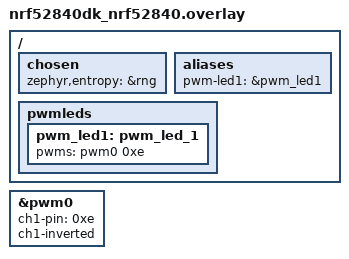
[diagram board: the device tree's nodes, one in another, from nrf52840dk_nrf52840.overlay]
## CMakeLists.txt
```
#
# Copyright (c) 2021 Nordic Semiconductor ASA
#
# SPDX-License-Identifier: LicenseRef-BSD-5-Clause-Nordic
#

cmake_minimum_required(VERSION 3.13.1)

get_filename_component(CHIP_ROOT ../../../../modules/lib/connectedhomeip REALPATH)
get_filename_component(COMMON_ROOT ../common REALPATH)

list(APPEND ZEPHYR_EXTRA_MODULES ${CHIP_ROOT}/config/nrfconnect/chip-module)
find_package(Zephyr HINTS $ENV{ZEPHYR_BASE})

project(chip-light-bulb)

# Temporary get rid of compilation warnings till zephyrproject-rtos/zephyr/pull/31471 is fetched
zephyr_compile_options(-Wno-parentheses)

target_include_directories(app PRIVATE src ${COMMON_ROOT}/src)

target_sources(app PRIVATE
               src/app_task.cpp
               src/lighting_manager.cpp
               src/light_bulb_publish_service.cpp
               src/gen/call-command-handler.cpp
               src/gen/callback-stub.cpp
               src/main.cpp
               src/zcl_callbacks.cpp
               ${COMMON_ROOT}/src/led_widget.cpp
               ${COMMON_ROOT}/src/nfc_widget.cpp
               ${COMMON_ROOT}/src/thread_util.cpp
               ${CHIP_ROOT}/src/app/server/DataModelHandler.cpp
               ${CHIP_ROOT}/src/app/reporting/reporting-default-configuration.cpp
               ${CHIP_ROOT}/src/app/reporting/reporting.cpp
               ${CHIP_ROOT}/src/app/util/af-event.cpp
               ${CHIP_ROOT}/src/app/util/af-main-common.cpp
               ${CHIP_ROOT}/src/app/util/attribute-size.cpp
               ${CHIP_ROOT}/src/app/util/attribute-storage.cpp
               ${CHIP_ROOT}/src/app/util/attribute-table.cpp
               ${CHIP_ROOT}/src/app/util/binding-table.cpp
               ${CHIP_ROOT}/src/app/util/chip-message-send.cpp
               ${CHIP_ROOT}/src/app/util/client-api.cpp
               ${CHIP_ROOT}/src/app/util/ember-print.cpp
               ${CHIP_ROOT}/src/app/util/message.cpp
               ${CHIP_ROOT}/src/app/util/process-cluster-message.cpp
               ${CHIP_ROOT}/src/app/util/process-global-message.cpp
               ${CHIP_ROOT}/src/app/util/util.cpp
               ${CHIP_ROOT}/src/app/clusters/on-off-server/on-off.cpp
               ${CHIP_ROOT}/src/app/clusters/level-control/level-control.cpp)
```

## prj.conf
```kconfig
#
# Copyright (c) 2021 Nordic Semiconductor ASA
#
# SPDX-License-Identifier: LicenseRef-Nordic-5-Clause
#

# Enable CHIP
CONFIG_CHIP=y
CONFIG_CHIP_PROJECT_CONFIG="src/chip_project_config.h"
CONFIG_STD_CPP14=y

# General networking settings
CONFIG_NETWORKING=y
CONFIG_NET_IPV6_NBR_CACHE=n
CONFIG_NET_IPV6_MLD=n
CONFIG_NET_SOCKETS_POLL_MAX=5

# Enable OpenThread MTD
CONFIG_NET_L2_OPENTHREAD=y

CONFIG_OPENTHREAD_MTD=y
CONFIG_OPENTHREAD_FTD=n
CONFIG_OPENTHREAD_SLAAC=y
CONFIG_OPENTHREAD_MTD_NETDIAG=y
CONFIG_OPENTHREAD_MANUAL_START=y
CONFIG_OPENTHREAD_THREAD_STACK_SIZE=6144
CONFIG_OPENTHREAD_NUM_MESSAGE_BUFFERS=64

CONFIG_OPENTHREAD_PANID=4660
CONFIG_OPENTHREAD_CHANNEL=15
CONFIG_OPENTHREAD_NETWORK_NAME="OpenThread"
CONFIG_OPENTHREAD_XPANID="11:11:11:11:22:22:22:22"

# Enable Bluetooth Low Energy
CONFIG_BT=y
CONFIG_BT_PERIPHERAL=y
CONFIG_BT_DEVICE_APPEARANCE=0
CONFIG_BT_DEVICE_NAME_DYNAMIC=y
CONFIG_BT_DEVICE_NAME_MAX=15
CONFIG_BT_DEVICE_NAME="ChipLight"
CONFIG_BT_MAX_CONN=1
CONFIG_BT_PHY_UPDATE=n
CONFIG_BT_CTLR_PHY_2M=n
CONFIG_BT_SMP=y
CONFIG_BT_PRIVACY=y
CONFIG_BT_MAX_PAIRED=0
CONFIG_BT_BONDABLE=n
CONFIG_BT_TINYCRYPT_ECC=n
CONFIG_BT_SMP_OOB_LEGACY_PAIR_ONLY=y
CONFIG_SDC_MAX_CONN_EVENT_LEN_DEFAULT=3000

# Use NFC to share commissioning information
CONFIG_CHIP_NFC_COMMISSIONING=y

# Use nrf_security
CONFIG_OPENTHREAD_NRF_SECURITY_CHOICE=y

CONFIG_CC3XX_BACKEND=y
CONFIG_OBERON_BACKEND=y

CONFIG_MBEDTLS_ENABLE_HEAP=y
CONFIG_MBEDTLS_HEAP_SIZE=15360
CONFIG_MBEDTLS_TLS_LIBRARY=y
CONFIG_NRF_SECURITY_ADVANCED=y

CONFIG_MBEDTLS_AES_C=y
CONFIG_MBEDTLS_ECP_C=y
CONFIG_MBEDTLS_ECP_DP_SECP256R1_ENABLED=y
CONFIG_MBEDTLS_CTR_DRBG_C=y
CONFIG_MBEDTLS_CIPHER_MODE_CTR=y
CONFIG_MBEDTLS_ECJPAKE_C=y
CONFIG_MBEDTLS_SHA256_C=y
CONFIG_MBEDTLS_PK_C=y
CONFIG_MBEDTLS_PK_WRITE_C=y
CONFIG_MBEDTLS_X509_CREATE_C=y
CONFIG_MBEDTLS_X509_CSR_WRITE_C=y

# Use SHA256 implementation from Oberon
CONFIG_CHOICE_OBERON_MBEDTLS_SHA256_C=y

# Disable unneeded crypto operations
CONFIG_MBEDTLS_SHA512_C=n
CONFIG_MBEDTLS_CIPHER_MODE_XTS=n
CONFIG_MBEDTLS_CHACHA20_C=n
CONFIG_MBEDTLS_POLY1305_C=n
CONFIG_MBEDTLS_CHACHAPOLY_C=n
CONFIG_MBEDTLS_GCM_C=n
CONFIG_MBEDTLS_RSA_C=n
CONFIG_OBERON_MBEDTLS_AES_C=n

# Add support for LEDs and buttons on Nordic development kits
CONFIG_DK_LIBRARY=y
CONFIG_PWM=y

# Other settings
CONFIG_LOG=y
CONFIG_LOG_MODE_MINIMAL=y
CONFIG_MAIN_STACK_SIZE=8192
CONFIG_INIT_STACKS=y
CONFIG_HW_STACK_PROTECTION=y
CONFIG_THREAD_NAME=y
CONFIG_SHELL=y
```

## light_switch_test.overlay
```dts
CONFIG_CHIP_ENABLE_RENDEZVOUS_BYPASS=y
```

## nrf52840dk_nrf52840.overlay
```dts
/*
 * Copyright (c) 2021 Nordic Semiconductor ASA
 *
 * SPDX-License-Identifier: LicenseRef-BSD-5-Clause-Nordic
 */

/ {

	/*
	* In some default configurations within the nRF Connect SDK,
	* e.g. on nRF52840, the chosen zephyr,entropy node is &cryptocell.
	* This devicetree overlay ensures that default is overridden wherever it
	* is set, as this application uses the RNG node for entropy exclusively.
	*/

	chosen {
		zephyr,entropy = &rng;
	};

	/*
	* By default, PWM module is only configured for led0 (LED1 on the board).
	* The lighting-app, however, uses LED2 to show the state of the lighting,
	* including its brightness level.
	*/
	aliases {
		pwm-led1 = &pwm_led1;
	};

	pwmleds {
		pwm_led1: pwm_led_1 {
			pwms = < &pwm0 0xe >;
		};
	};

};

&pwm0 {
	ch1-pin = < 0xe >;
	ch1-inverted;
};
```

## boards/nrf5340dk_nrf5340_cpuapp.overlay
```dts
/*
 * Copyright (c) 2021 Nordic Semiconductor ASA
 *
 * SPDX-License-Identifier: LicenseRef-Nordic-5-Clause
 */

/ {
	/*
	* By default, PWM module is only configured for led0 (LED1 on the board).
	* The lighting-app, however, uses LED2 to show the state of the lighting,
	* including its brightness level.
	*/
	aliases {
		pwm-led1 = &pwm_led1;
	};

	pwmleds {
		compatible = "pwm-leds";
		pwm_led1: pwm_led_1 {
			pwms = < &pwm0 0x1d >;
		};
	};

};

&pwm0 {
	ch1-pin = < 0x1d >;
	ch1-inverted;
};
```

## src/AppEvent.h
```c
/*
 * Copyright (c) 2020 Nordic Semiconductor ASA
 *
 * SPDX-License-Identifier: LicenseRef-BSD-5-Clause-Nordic
 */

#pragma once

#include <cstdint>

struct AppEvent {
	enum LightEventType : uint8_t {
		On,
		Off,
		Toggle,
		Level
	};

	enum OtherEventType : uint8_t {
		FactoryReset = Level + 1,
		StartThread,
		StartBleAdvertising,
		PublishLightBulbService
	};

	AppEvent() = default;

	AppEvent(LightEventType type, uint8_t value, bool chipInitiated) : Type(type), Value(value), LightEvent{chipInitiated}
	{
	}

	AppEvent(OtherEventType type) : Type(type)
	{
	}

	uint8_t Type;
	uint8_t Value;

	union {
		struct {
			// was the event triggered by CHIP Data Model layer
			bool ChipInitiated;
		} LightEvent;
	};
};
```

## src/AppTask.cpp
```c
/*
 * Copyright (c) 2020 Nordic Semiconductor ASA
 *
 * SPDX-License-Identifier: LicenseRef-BSD-5-Clause-Nordic
 */

#include "AppTask.h"

#include "LightingManager.h"
#include "QRCodeUtil.h"
#include "Server.h"
#include "LEDWidget.h"
#include "ThreadUtil.h"
#include "LightBulbPublishService.h"

#ifdef CONFIG_CHIP_NFC_COMMISSIONING
#include "NFCWidget.h"
#endif

#include "attribute-storage.h"
#include "gen/cluster-id.h"

#include <platform/CHIPDeviceLayer.h>

#include <dk_buttons_and_leds.h>
#include <logging/log.h>
#include <zephyr.h>

using namespace ::chip::DeviceLayer;

LOG_MODULE_DECLARE(app);
K_MSGQ_DEFINE(sAppEventQueue, sizeof(AppEvent), AppTask::APP_EVENT_QUEUE_SIZE, alignof(AppEvent));

namespace {
LEDWidget sStatusLED;
LEDWidget sLightLED;

#ifdef CONFIG_CHIP_NFC_COMMISSIONING
NFCWidget sNFC;
#endif

LightBulbPublishService sLightBulbPublishService;

bool sIsThreadProvisioned;
bool sIsThreadEnabled;
bool sIsThreadAttached;
bool sIsPairedToAccount;
bool sHaveBLEConnections;
bool sHaveServiceConnectivity;
} // namespace

AppTask AppTask::sAppTask;

int AppTask::Init()
{
	// Initialize LEDs
	LEDWidget::InitGpio();

	sStatusLED.Init(DK_LED1);
	sLightLED.Init(DK_LED2);
	sLightLED.Set(false);

	// Initialize buttons
	int ret = dk_buttons_init(ButtonEventHandler);
	if (ret) {
		LOG_ERR("dk_buttons_init() failed");
		return ret;
	}

	// Initialize light manager
	LightingMgr().Init(DT_PWMS_LABEL(DT_ALIAS(pwm_led1)),
			   DT_PWMS_CHANNEL(DT_ALIAS(pwm_led1)));

	LightingMgr().SetCallbacks(ActionInitiated, ActionCompleted);

	// Init ZCL Data Model and start server
	InitServer();
	PrintQRCode(chip::RendezvousInformationFlags::kBLE);

#ifdef CONFIG_CHIP_NFC_COMMISSIONING
	ret = sNFC.Init(ConnectivityMgr());
	if (ret) {
		LOG_ERR("NFC initialization failed");
		return ret;
	}

	PlatformMgr().AddEventHandler(AppTask::ThreadProvisioningHandler, 0);
#endif

	sLightBulbPublishService.Init();

	return 0;
}

int AppTask::StartApp()
{
	int ret = Init();

	if (ret) {
		LOG_ERR("AppTask.Init() failed");
		return ret;
	}

	AppEvent event = {};

	while (true) {
		ret = k_msgq_get(&sAppEventQueue, &event, K_MSEC(10));

		while (!ret) {
			DispatchEvent(event);
			ret = k_msgq_get(&sAppEventQueue, &event, K_NO_WAIT);
		}

		// Collect connectivity and configuration state from the CHIP stack.  Because the
		// CHIP event loop is being run in a separate task, the stack must be locked
		// while these values are queried.  However we use a non-blocking lock request
		// (TryLockChipStack()) to avoid blocking other UI activities when the CHIP
		// task is busy (e.g. with a long crypto operation).

		if (PlatformMgr().TryLockChipStack()) {
			sIsThreadProvisioned = ConnectivityMgr().IsThreadProvisioned();
			sIsThreadEnabled = ConnectivityMgr().IsThreadEnabled();
			sIsThreadAttached = ConnectivityMgr().IsThreadAttached();
			sHaveBLEConnections = (ConnectivityMgr().NumBLEConnections() != 0);
			sHaveServiceConnectivity = ConnectivityMgr().HaveServiceConnectivity();
			PlatformMgr().UnlockChipStack();
		}

		// Consider the system to be "fully connected" if it has service
		// connectivity and it is able to interact with the service on a regular basis.
		bool isFullyConnected = sHaveServiceConnectivity;

		// Update the status LED.
		//
		// If system has "full connectivity", keep the LED On constantly.
		//
		// If thread and service provisioned, but not attached to the thread network yet OR no
		// connectivity to the service OR subscriptions are not fully established
		// THEN blink the LED Off for a short period of time.
		//
		// If the system has ble connection(s) uptill the stage above, THEN blink the LEDs at an even
		// rate of 100ms.
		//
		// Otherwise, blink the LED ON for a very short time.
		if (isFullyConnected) {
			sStatusLED.Set(true);
		} else if (sIsThreadProvisioned && sIsThreadEnabled && sIsPairedToAccount) {
			sStatusLED.Blink(950, 50);
		} else if (sHaveBLEConnections) {
			sStatusLED.Blink(100, 100);
		} else {
			sStatusLED.Blink(50, 950);
		}

		sStatusLED.Animate();
	}
}

void AppTask::PostEvent(const AppEvent& aEvent)
{
	if (k_msgq_put(&sAppEventQueue, &aEvent, K_NO_WAIT)) {
		LOG_INF("Failed to post event to app task event queue");
	}
}

void AppTask::UpdateClusterState()
{
	uint8_t onOff = LightingMgr().IsTurnedOn();

	// write the new on/off value
	EmberAfStatus status = emberAfWriteAttribute(1, ZCL_ON_OFF_CLUSTER_ID, ZCL_ON_OFF_ATTRIBUTE_ID, CLUSTER_MASK_SERVER, &onOff,
						     ZCL_BOOLEAN_ATTRIBUTE_TYPE);

	if (status != EMBER_ZCL_STATUS_SUCCESS) {
		LOG_ERR("Updating on/off cluster failed: %x", status);
	}

	uint8_t level = LightingMgr().GetLevel();

	status = emberAfWriteAttribute(1, ZCL_LEVEL_CONTROL_CLUSTER_ID, ZCL_CURRENT_LEVEL_ATTRIBUTE_ID, CLUSTER_MASK_SERVER, &level,
					ZCL_DATA8_ATTRIBUTE_TYPE);

	if (status != EMBER_ZCL_STATUS_SUCCESS) {
		LOG_ERR("Updating level cluster failed: %x", status);
	}
}

void AppTask::DispatchEvent(const AppEvent& aEvent)
{
	switch (aEvent.Type) {
	case AppEvent::On:
		LightingMgr().InitiateAction(LightingManager::Action::On, aEvent.Value, aEvent.LightEvent.ChipInitiated);
		break;
	case AppEvent::Off:
		LightingMgr().InitiateAction(LightingManager::Action::Off, aEvent.Value, aEvent.LightEvent.ChipInitiated);
		break;
	case AppEvent::Toggle:
		LightingMgr().InitiateAction(LightingMgr().IsTurnedOn() ? LightingManager::Action::Off : LightingManager::Action::On,
					     aEvent.Value, aEvent.LightEvent.ChipInitiated);
		break;
	case AppEvent::Level:
		LightingMgr().InitiateAction(LightingManager::Action::Level, aEvent.Value, aEvent.LightEvent.ChipInitiated);
		break;
	case AppEvent::FactoryReset:
		LOG_INF("Factory Reset triggered");
		ConfigurationMgr().InitiateFactoryReset();
		break;
	case AppEvent::StartThread:
		StartThreadHandler();
		break;
	case AppEvent::StartBleAdvertising:
		StartBLEAdvertisingHandler();
		break;
	case AppEvent::PublishLightBulbService:
		sLightBulbPublishService.Publish();
		break;
	default:
		LOG_INF("Unknown event received");
		break;
	}
}

void AppTask::ActionInitiated(LightingManager::Action aAction)
{
    if (aAction == LightingManager::Action::On)
    {
        LOG_INF("Turn On Action has been initiated");
    }
    else if (aAction == LightingManager::Action::Off)
    {
        LOG_INF("Turn Off Action has been initiated");
    }
    else if (aAction == LightingManager::Action::Level)
    {
        LOG_INF("Level Action has been initiated");
    }
}

void AppTask::ActionCompleted(LightingManager::Action aAction)
{
    if (aAction == LightingManager::Action::On)
    {
        LOG_INF("Turn On Action has been completed");
    }
    else if (aAction == LightingManager::Action::Off)
    {
        LOG_INF("Turn Off Action has been completed");
    }
    else if (aAction == LightingManager::Action::Level)
    {
        LOG_INF("Level Action has been completed");
    }

    if (!LightingMgr().IsActionChipInitiated())
    {
        sAppTask.UpdateClusterState();
    }
}

void AppTask::StartThreadHandler()
{
	if (!ConnectivityMgr().IsThreadProvisioned()) {
		StartDefaultThreadNetwork();
		LOG_INF("Device is not commissioned to a Thread network. Starting with the default configuration");
	} else {
		LOG_INF("Device is commissioned to a Thread network");
	}

	sLightBulbPublishService.Start(10000, 1000);
}

void AppTask::StartBLEAdvertisingHandler()
{
    if (!sNFC.IsTagEmulationStarted())
    {
        if (!(GetAppTask().StartNFCTag() < 0))
        {
            LOG_INF("Started NFC Tag emulation");
        }
        else
        {
            LOG_ERR("Starting NFC Tag failed");
        }
    }
    else
    {
        LOG_INF("NFC Tag emulation is already started");
    }

	if (!ConnectivityMgr().IsBLEAdvertisingEnabled()) {
		ConnectivityMgr().SetBLEAdvertisingEnabled(true);
		LOG_INF("Enabled BLE Advertising");
	} else {
		LOG_INF("BLE Advertising is already enabled");
	}
}

#ifdef CONFIG_CHIP_NFC_COMMISSIONING
int AppTask::StartNFCTag()
{
	// Get QR Code and emulate its content using NFC tag
	uint32_t setupPinCode;
	std::string QRCode;

	int result = GetQRCode(setupPinCode, QRCode, chip::RendezvousInformationFlags::kBLE);

	VerifyOrExit(!result, ChipLogError(AppServer, "Getting QR code payload failed"));

	result = sNFC.StartTagEmulation(QRCode.c_str(), QRCode.size());
	VerifyOrExit(result >= 0, ChipLogError(AppServer, "Starting NFC Tag emulation failed"));

exit:
	return result;
}

void AppTask::ThreadProvisioningHandler(const ChipDeviceEvent *event, intptr_t arg)
{
	ARG_UNUSED(arg);
	if ((event->Type == DeviceEventType::kServiceProvisioningChange) && ConnectivityMgr().IsThreadProvisioned()) {
		const int result = sNFC.StopTagEmulation();
		if (result) {
			LOG_ERR("Stopping NFC Tag emulation failed");
		}
	}
}
#endif

void AppTask::ButtonEventHandler(uint32_t button_state, uint32_t has_changed)
{
	if (DK_BTN1_MSK & button_state & has_changed) {
		GetAppTask().PostEvent(AppEvent{ AppEvent::FactoryReset });
	}

	if (DK_BTN2_MSK & button_state & has_changed) {
		GetAppTask().PostEvent(AppEvent{ AppEvent::Toggle, 0, false });
	}

	if (DK_BTN3_MSK & button_state & has_changed) {
		GetAppTask().PostEvent(AppEvent{ AppEvent::StartThread });
	}

	if (DK_BTN4_MSK & button_state & has_changed) {
		GetAppTask().PostEvent(AppEvent{ AppEvent::StartBleAdvertising });
	}
}
```

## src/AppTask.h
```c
/*
 * Copyright (c) 2020 Nordic Semiconductor ASA
 *
 * SPDX-License-Identifier: LicenseRef-BSD-5-Clause-Nordic
 */

#pragma once

#include "AppEvent.h"
#include "LightingManager.h"

#include <platform/CHIPDeviceLayer.h>

struct k_timer;

class AppTask {
public:
	static constexpr size_t APP_EVENT_QUEUE_SIZE = 10;

	int StartApp();

	void PostEvent(const AppEvent& aEvent);
	void UpdateClusterState();

private:
	int Init();

	void DispatchEvent(const AppEvent& event);
	void CompleteLockActionHandler();
	void StartThreadHandler();
	void StartBLEAdvertisingHandler();

#ifdef CONFIG_CHIP_NFC_COMMISSIONING
	int StartNFCTag();
#endif

	static void ActionInitiated(LightingManager::Action aAction);
	static void ActionCompleted(LightingManager::Action aAction);
	static void ButtonEventHandler(uint32_t buttons_state, uint32_t has_changed);
	static void ThreadProvisioningHandler(const chip::DeviceLayer::ChipDeviceEvent *event, intptr_t arg);

	friend AppTask & GetAppTask();

	static AppTask sAppTask;
};

inline AppTask & GetAppTask()
{
	return AppTask::sAppTask;
}
```

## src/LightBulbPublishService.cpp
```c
/*
 * Copyright (c) 2020 Nordic Semiconductor ASA
 *
 * SPDX-License-Identifier: LicenseRef-BSD-5-Clause-Nordic
 */
#include "LightBulbPublishService.h"

#include "AppTask.h"

#include <logging/log.h>
#include <zephyr.h>

#include <openthread/message.h>
#include <openthread/udp.h>
#include <platform/OpenThread/OpenThreadUtils.h>

#include <inet/InetConfig.h>
#include <platform/CHIPDeviceLayer.h>
#include <transport/TransportMgr.h>
#include <transport/raw/UDP.h>

LOG_MODULE_DECLARE(app);

// Pointer to the LightBulbPublishService instance needed by static
// PublishTimerHandler method
static LightBulbPublishService* sLightBulbPublishService;

const char PUBLISH_SERVICE_PAYLOAD[] = "chip-light-bulb";
const char PUBLISH_DEST_ADDR[] = "ff03::1:12345";

using namespace ::chip;
using namespace ::chip::Inet;
using namespace ::chip::Transport;
using namespace ::chip::DeviceLayer;

void LightBulbPublishService::Init()
{
    // Set pointer to the current instance
    sLightBulbPublishService = this;
    mIsServiceStarted = false;

    // Initialize timer
    k_timer_init(&mPublishTimer, &PublishTimerHandler, nullptr);
    k_timer_user_data_set(&mPublishTimer, this);

    // Initialize UDP endpoint
    UdpListenParameters udpParams(&chip::DeviceLayer::InetLayer);
    udpParams.SetAddressType(kIPAddressType_IPv6);
    udpParams.SetInterfaceId(INET_NULL_INTERFACEID);
    udpParams.SetListenPort(SERVICE_UDP_PORT);
    if (mUdp.Init(udpParams))
    {
        LOG_ERR("LightBulbPublishService initialization failed");
    }

    mMessageId = 0;
    IPAddress::FromString(PUBLISH_DEST_ADDR, mPublishDestAddr);
}

void LightBulbPublishService::Start(uint32_t aTimeoutInMs, uint32_t aIntervalInMs)
{
    if (!mIsServiceStarted)
    {
        if (aTimeoutInMs >= aIntervalInMs)
        {
            LOG_INF("Started Publish service");

            mPublishInterval = aIntervalInMs;
            // Calculate number of publish iterations to do considering given timeout and interval values.
            mPublishIterations = aTimeoutInMs / aIntervalInMs;
            mIsServiceStarted = true;

            k_timer_start(&mPublishTimer, K_MSEC(aIntervalInMs), K_NO_WAIT);
        }
        else
        {
            LOG_ERR("Publish service cannot be started: service timeout is greater than interval");
        }
    }
    else
    {
        LOG_INF("Publish service is already running");
    }
}

void LightBulbPublishService::Stop()
{
    if (mIsServiceStarted)
    {
        LOG_INF("Stopped Publish service");

        k_timer_stop(&mPublishTimer);

        mIsServiceStarted = false;
        mMessageId = 0;
    }
    else
    {
        LOG_INF("Publish service is not running");
    }
}

void LightBulbPublishService::Publish()
{
    if (!chip::DeviceLayer::ConnectivityMgrImpl().IsThreadAttached())
    {
        return;
    }

    const uint16_t payloadLength = sizeof(PUBLISH_SERVICE_PAYLOAD);

    chip::System::PacketBufferHandle buffer = chip::System::PacketBuffer::NewWithAvailableSize(payloadLength);
    if (!buffer.IsNull())
    {
        memcpy(buffer->Start(), PUBLISH_SERVICE_PAYLOAD, payloadLength);
        buffer->SetDataLength(payloadLength);

        // Subsequent messages are assumed to have increasing IDs.
        PacketHeader header;
        header.SetMessageId(mMessageId++);

        if (mUdp.SendMessage(header, Transport::PeerAddress::UDP(mPublishDestAddr), std::move(buffer)))
        {
            LOG_INF("LightBulbPublishService message send successfully");
        }
        else
        {
            LOG_INF("LightBulbPublishService message sending failed");
        }
    }
}

void LightBulbPublishService::PublishTimerHandler(k_timer *aTimer)
{
    if (sLightBulbPublishService->mPublishIterations > 0)
    {
        GetAppTask().PostEvent(AppEvent{ AppEvent::PublishLightBulbService });
        k_timer_start(&(sLightBulbPublishService->mPublishTimer), K_MSEC(sLightBulbPublishService->mPublishInterval), K_NO_WAIT);
        sLightBulbPublishService->mPublishIterations--;
    }
    else
    {
        sLightBulbPublishService->Stop();
    }
}
```

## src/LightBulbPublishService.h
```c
/*
 * Copyright (c) 2020 Nordic Semiconductor ASA
 *
 * SPDX-License-Identifier: LicenseRef-BSD-5-Clause-Nordic
 */
#pragma once

#include <inet/InetConfig.h>
#include <transport/raw/UDP.h>

#include <zephyr.h>

#include <string>

using namespace ::chip::Inet;
using namespace ::chip::Transport;

class LightBulbPublishService
{
public:
    void Init();
    void Start(uint32_t aTimeoutInMs, uint32_t aIntervalInMs);
    void Stop();
    void Publish();
    
private:
    friend LightBulbPublishService & LightBulbPublishServ();

    static constexpr uint16_t SERVICE_UDP_PORT = 13000;

    bool mIsServiceStarted;
    uint32_t mPublishInterval;
    uint32_t mPublishIterations;
    k_timer mPublishTimer;
    UDP mUdp;
    uint32_t mMessageId;
    IPAddress mPublishDestAddr;

    static void PublishTimerHandler(k_timer *aTimer);

};
```

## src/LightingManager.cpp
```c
/*
 * Copyright (c) 2020 Nordic Semiconductor ASA
 *
 * SPDX-License-Identifier: LicenseRef-BSD-5-Clause-Nordic
 */

#include "LightingManager.h"

#include <logging/log.h>

#include <drivers/pwm.h>
#include <zephyr.h>

LOG_MODULE_DECLARE(app);

LightingManager LightingManager::sLight;

int LightingManager::Init(const char * pwmDeviceName, uint32_t pwmChannel)
{
    // We use a gpioPin instead of a LEDWidget here because we want to use PWM
    // and other features instead of just on/off.

    mState      = State::On;
    mLevel      = kMaxLevel;
    mPwmDevice  = device_get_binding(pwmDeviceName);
    mPwmChannel = pwmChannel;

    if (!mPwmDevice)
    {
        LOG_ERR("Cannot find PWM device %s", log_strdup(pwmDeviceName));
        return -ENODEV;
    }

    Set(false);
    return 0;
}

void LightingManager::SetCallbacks(LightingCallback_fn aActionInitiated_CB, LightingCallback_fn aActionCompleted_CB)
{
    mActionInitiated_CB = aActionInitiated_CB;
    mActionCompleted_CB = aActionCompleted_CB;
}

bool LightingManager::InitiateAction(Action aAction, uint8_t value, bool chipInitiated)
{
    bool actionInitiated = false;
    State newState;

    // Initiate On/Off Action only when the previous one is complete.
    if (mState == State::Off && aAction == Action::On)
    {
        actionInitiated = true;
        newState        = State::On;
    }
    else if (mState == State::On && aAction == Action::Off)
    {
        actionInitiated = true;
        newState        = State::Off;
    }
    else if (aAction == Action::Level && value != mLevel)
    {
        actionInitiated = true;
        newState = (value == 0) ? State::Off : State::On;
    }

    if (actionInitiated)
    {
        if (mActionInitiated_CB)
        {
            mActionInitiated_CB(aAction);
        }

        if (aAction == Action::On || aAction == Action::Off)
        {
            Set(newState == State::On);
        }
        else if (aAction == Action::Level)
        {
            SetLevel(value);
        }

        mChipInitiatedAction = chipInitiated;

        if (mActionCompleted_CB)
        {
            mActionCompleted_CB(aAction);
        }
    }

    return actionInitiated;
}

void LightingManager::SetLevel(uint8_t aLevel)
{
    LOG_INF("Setting brightness level to %u", aLevel);
    mLevel = aLevel;
    UpdateLight();
}

void LightingManager::Set(bool aOn)
{
    mState = aOn ? State::On : State::Off;
    UpdateLight();
}

void LightingManager::UpdateLight()
{
    constexpr uint32_t kPwmWidthUs = 1000u;
    const uint8_t level            = mState == State::On ? mLevel : 0;
    pwm_pin_set_usec(mPwmDevice, mPwmChannel, kPwmWidthUs, kPwmWidthUs * level / kMaxLevel, 0);
}
```

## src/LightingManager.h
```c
/*
 * Copyright (c) 2020 Nordic Semiconductor ASA
 *
 * SPDX-License-Identifier: LicenseRef-BSD-5-Clause-Nordic
 */

#pragma once

#include "AppEvent.h"

#include <cstdint>
#include <drivers/gpio.h>

class LightingManager
{
public:
    enum class Action : uint8_t
    {
        On,
        Off,
        Level
    };

    enum class State : uint8_t
    {
        On,
        Off
    };

    using LightingCallback_fn = void (*)(Action);

    int Init(const char * pwmDeviceName, uint32_t pwmChannel);
    bool IsTurnedOn() const { return mState == State::On; }
    uint8_t GetLevel() const { return mLevel; }
    bool IsActionChipInitiated() const { return mChipInitiatedAction; }
    bool InitiateAction(Action aAction, uint8_t value, bool chipInitiated);
    void SetCallbacks(LightingCallback_fn aActionInitiated_CB, LightingCallback_fn aActionCompleted_CB);

private:
    static constexpr uint8_t kMaxLevel = 255;

    friend LightingManager & LightingMgr();
    State mState;
    uint8_t mLevel;
    const device * mPwmDevice;
    uint32_t mPwmChannel;
    bool mChipInitiatedAction;

    LightingCallback_fn mActionInitiated_CB;
    LightingCallback_fn mActionCompleted_CB;

    void Set(bool aOn);
    void SetLevel(uint8_t aLevel);
    void UpdateLight();

    static LightingManager sLight;
};

inline LightingManager & LightingMgr(void)
{
    return LightingManager::sLight;
}
```

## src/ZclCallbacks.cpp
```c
/*
 * Copyright (c) 2020 Nordic Semiconductor ASA
 *
 * SPDX-License-Identifier: LicenseRef-BSD-5-Clause-Nordic
 */

#include <support/logging/CHIPLogging.h>

#include "AppTask.h"
#include "LightingManager.h"

#include "af.h"
#include "gen/attribute-id.h"
#include "gen/cluster-id.h"
#include <app/util/af-types.h>

using namespace ::chip;

void emberAfPostAttributeChangeCallback(EndpointId endpoint, ClusterId clusterId, AttributeId attributeId, uint8_t mask,
					uint16_t manufacturerCode, uint8_t type, uint8_t size, uint8_t *value)
{
	ChipLogProgress(Zcl, "Cluster callback: %d", clusterId);

	if (clusterId == ZCL_ON_OFF_CLUSTER_ID) 
	{
		if (attributeId != ZCL_ON_OFF_ATTRIBUTE_ID) 
		{
			ChipLogProgress(Zcl, "Unknown attribute ID: %d", attributeId);
			return;
		}

		GetAppTask().PostEvent(AppEvent(*value ? AppEvent::On : AppEvent::Off, *value, true));
	}
	else if (clusterId == ZCL_LEVEL_CONTROL_CLUSTER_ID) 
	{
		if (attributeId != ZCL_MOVE_TO_LEVEL_COMMAND_ID)
		{
			ChipLogProgress(Zcl, "Unknown attribute ID: %d", attributeId);
			return;
		}

		if (size == 1)
		{
			ChipLogProgress(Zcl, "emberAfPostAttributeChangeCallback %d", *value);
			GetAppTask().PostEvent(AppEvent(AppEvent::Level, *value, true));
		}
		else
		{
			ChipLogError(Zcl, "wrong length for level: %d", size);
		}
	}
	else 
	{
		ChipLogProgress(Zcl, "Unknown cluster ID: %d", clusterId);
		return;
	}
}

/** @brief OnOff Cluster Init
 *
 * This function is called when a specific cluster is initialized. It gives the
 * application an opportunity to take care of cluster initialization procedures.
 * It is called exactly once for each endpoint where cluster is present.
 *
 * @param endpoint   Ver.: always
 *
 * TODO Issue #3841
 * emberAfOnOffClusterInitCallback happens before the stack initialize the cluster
 * attributes to the default value.
 * The logic here expects something similar to the deprecated Plugins callback
 * emberAfPluginOnOffClusterServerPostInitCallback.
 *
 */
void emberAfOnOffClusterInitCallback(EndpointId endpoint)
{
	GetAppTask().UpdateClusterState();
}
```

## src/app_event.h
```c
/*
 * Copyright (c) 2021 Nordic Semiconductor ASA
 *
 * SPDX-License-Identifier: LicenseRef-BSD-5-Clause-Nordic
 */

#pragma once

#include <cstdint>

struct AppEvent {
	enum LightEventType : uint8_t { On, Off, Toggle, Level };

	enum OtherEventType : uint8_t {
		FactoryReset = Level + 1,
		StartThread,
		StartBleAdvertising,
		PublishLightBulbService
	};

	AppEvent() = default;

	AppEvent(LightEventType type, uint8_t value, bool chipInitiated)
		: Type(type), LightEvent{ value, chipInitiated }
	{
	}

	AppEvent(OtherEventType type) : Type(type) {}

	uint8_t Type;

	union {
		struct {
			/* value indicating light brightness in the scope (0-255) */
			uint8_t Value;
			/* was the event triggered by CHIP Data Model layer */
			bool ChipInitiated;
		} LightEvent;
	};
};
```

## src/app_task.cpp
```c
/*
 * Copyright (c) 2021 Nordic Semiconductor ASA
 *
 * SPDX-License-Identifier: LicenseRef-Nordic-5-Clause
 */

#include "app_task.h"

#include "lighting_manager.h"
#include "led_widget.h"
#include "thread_util.h"
#include "light_bulb_publish_service.h"

#include <platform/CHIPDeviceLayer.h>

#include <app/server/OnboardingCodesUtil.h>
#include <app/server/Server.h>
#include <app/util/attribute-storage.h>
#include "gen/attribute-id.h"
#include "gen/attribute-type.h"
#include "gen/cluster-id.h"

/* MCUMgr BT FOTA includes */
#ifdef CONFIG_MCUMGR_CMD_OS_MGMT
#include "os_mgmt/os_mgmt.h"
#endif
#ifdef CONFIG_MCUMGR_CMD_IMG_MGMT
#include "img_mgmt/img_mgmt.h"
#endif
#ifdef CONFIG_MCUMGR_SMP_BT
#include <mgmt/mcumgr/smp_bt.h>
#endif
#ifdef CONFIG_BOOTLOADER_MCUBOOT
#include <dfu/mcuboot.h>
#endif

#include <dk_buttons_and_leds.h>
#include <logging/log.h>
#include <zephyr.h>

#include <algorithm>

using namespace ::chip::DeviceLayer;

#define PWM_LED DT_ALIAS(pwm_led1)

LOG_MODULE_DECLARE(app);
K_MSGQ_DEFINE(sAppEventQueue, sizeof(AppEvent), AppTask::APP_EVENT_QUEUE_SIZE, alignof(AppEvent));

namespace
{
static constexpr uint32_t kFactoryResetTriggerTimeout = 3000;
static constexpr uint32_t kFactoryResetCancelWindow = 3000;

LEDWidget sStatusLED;
LEDWidget sLightLED;
LEDWidget sUnusedLED;
LEDWidget sUnusedLED_1;

LightBulbPublishService sLightBulbPublishService;

bool sIsThreadProvisioned;
bool sIsThreadEnabled;
bool sHaveBLEConnections;
bool sHaveServiceConnectivity;

k_timer sFunctionTimer;
} /* namespace */

AppTask AppTask::sAppTask;

int AppTask::Init()
{
	/* Initialize LEDs */
	LEDWidget::InitGpio();

	sStatusLED.Init(DK_LED1);
	sLightLED.Init(DK_LED2);
	sLightLED.Set(false);
	sUnusedLED.Init(DK_LED3);
	sUnusedLED_1.Init(DK_LED4);

	/* Initialize buttons */
	int ret = dk_buttons_init(ButtonEventHandler);
	if (ret) {
		LOG_ERR("dk_buttons_init() failed");
		return ret;
	}

#ifdef CONFIG_BOOTLOADER_MCUBOOT
	/* Check if the image is run in the REVERT mode and eventually
	confirm it to prevent reverting on the next boot. */
	if (mcuboot_swap_type() == BOOT_SWAP_TYPE_REVERT) {
		if (boot_write_img_confirmed()) {
			LOG_ERR("Confirming firmware image failed, it will be reverted on the next boot.");
		} else {
			LOG_INF("New firmware image confirmed.");
		}
	}
#endif

	/* Initialize function timer */
	k_timer_init(&sFunctionTimer, &AppTask::TimerEventHandler, nullptr);
	k_timer_user_data_set(&sFunctionTimer, this);

	/* Initialize light manager */
	ret = LightingMgr().Init(DEVICE_DT_GET(DT_PWMS_CTLR(PWM_LED)), DT_PWMS_CHANNEL(PWM_LED));
	if (ret) {
		return ret;
	}

	LightingMgr().SetCallbacks(ActionInitiated, ActionCompleted);

	/* Init ZCL Data Model and start server */
	InitServer();
	ConfigurationMgr().LogDeviceConfig();
	PrintOnboardingCodes(chip::RendezvousInformationFlags(chip::RendezvousInformationFlag::kBLE));

#ifdef CONFIG_CHIP_NFC_COMMISSIONING
	PlatformMgr().AddEventHandler(AppTask::ThreadProvisioningHandler, 0);
#endif

	sLightBulbPublishService.Init();
	return 0;
}

int AppTask::StartApp()
{
	int ret = Init();

	if (ret) {
		LOG_ERR("AppTask.Init() failed");
		return ret;
	}

	AppEvent event = {};

	while (true) {
		ret = k_msgq_get(&sAppEventQueue, &event, K_MSEC(10));

		while (!ret) {
			DispatchEvent(event);
			ret = k_msgq_get(&sAppEventQueue, &event, K_NO_WAIT);
		}

		/* Collect connectivity and configuration state from the CHIP stack.  Because the
		 * CHIP event loop is being run in a separate task, the stack must be locked
		 * while these values are queried.  However we use a non-blocking lock request
		 * (TryLockChipStack()) to avoid blocking other UI activities when the CHIP
		 * task is busy (e.g. with a long crypto operation). */

		if (PlatformMgr().TryLockChipStack()) {
			sIsThreadProvisioned = ConnectivityMgr().IsThreadProvisioned();
			sIsThreadEnabled = ConnectivityMgr().IsThreadEnabled();
			sHaveBLEConnections = (ConnectivityMgr().NumBLEConnections() != 0);
			sHaveServiceConnectivity = ConnectivityMgr().HaveServiceConnectivity();
			PlatformMgr().UnlockChipStack();
		}

		/* Update the status LED.
		 *
		 * If system has "full connectivity", keep the LED On constantly.
		 *
		 * If thread and service provisioned, but not attached to the thread network yet OR no
		 * connectivity to the service OR subscriptions are not fully established
		 * THEN blink the LED Off for a short period of time.
		 *
		 * If the system has ble connection(s) uptill the stage above, THEN blink the LED at an even
		 * rate of 100ms.
		 *
		 * Otherwise, blink the LED On for a very short time. */
		if (sHaveServiceConnectivity) {
			sStatusLED.Set(true);
		} else if (sIsThreadProvisioned && sIsThreadEnabled) {
			sStatusLED.Blink(950, 50);
		} else if (sHaveBLEConnections) {
			sStatusLED.Blink(100, 100);
		} else {
			sStatusLED.Blink(50, 950);
		}

		sStatusLED.Animate();
		sUnusedLED.Animate();
		sUnusedLED_1.Animate();
	}
}

void AppTask::PostEvent(const AppEvent &aEvent)
{
	if (k_msgq_put(&sAppEventQueue, &aEvent, K_NO_WAIT)) {
		LOG_INF("Failed to post event to app task event queue");
	}
}

void AppTask::UpdateClusterState()
{
	uint8_t onOff = LightingMgr().IsTurnedOn();

	/* write the new on/off value */
	EmberAfStatus status = emberAfWriteAttribute(1, ZCL_ON_OFF_CLUSTER_ID, ZCL_ON_OFF_ATTRIBUTE_ID,
						     CLUSTER_MASK_SERVER, &onOff, ZCL_BOOLEAN_ATTRIBUTE_TYPE);

	if (status != EMBER_ZCL_STATUS_SUCCESS) {
		LOG_ERR("Updating on/off cluster failed: %x", status);
	}

	uint8_t level = LightingMgr().GetLevel();

	status = emberAfWriteAttribute(1, ZCL_LEVEL_CONTROL_CLUSTER_ID, ZCL_CURRENT_LEVEL_ATTRIBUTE_ID,
				       CLUSTER_MASK_SERVER, &level, ZCL_DATA8_ATTRIBUTE_TYPE);

	if (status != EMBER_ZCL_STATUS_SUCCESS) {
		LOG_ERR("Updating level cluster failed: %x", status);
	}
}

int AppTask::SoftwareUpdateConfirmationHandler(uint32_t offset, uint32_t size, void *arg)
{
	/* For now just print update progress and confirm data chunk without any additional checks. */
	LOG_INF("Software update progress %d B / %d B", offset, size);

	return 0;
}

void AppTask::DispatchEvent(const AppEvent &aEvent)
{
	switch (aEvent.Type) {
	case AppEvent::On:
		LightingMgr().InitiateAction(LightingManager::Action::On, aEvent.LightEvent.Value,
					     aEvent.LightEvent.ChipInitiated);
		break;
	case AppEvent::Off:
		LightingMgr().InitiateAction(LightingManager::Action::Off, aEvent.LightEvent.Value,
					     aEvent.LightEvent.ChipInitiated);
		break;
	case AppEvent::Toggle:
		LightingMgr().InitiateAction(LightingMgr().IsTurnedOn() ? LightingManager::Action::Off :
									  LightingManager::Action::On,
					     aEvent.LightEvent.Value, aEvent.LightEvent.ChipInitiated);
		break;
	case AppEvent::Level:
		LightingMgr().InitiateAction(LightingManager::Action::Level, aEvent.LightEvent.Value,
					     aEvent.LightEvent.ChipInitiated);
		break;
	case AppEvent::FunctionPress:
		FunctionPressHandler();
		break;
	case AppEvent::FunctionRelease:
		FunctionReleaseHandler();
		break;
	case AppEvent::FunctionTimer:
		FunctionTimerEventHandler();
	case AppEvent::StartThread:
		StartThreadHandler();
		break;
	case AppEvent::StartBleAdvertising:
		StartBLEAdvertisingHandler();
		break;
	case AppEvent::PublishLightBulbService:
		sLightBulbPublishService.Publish();
		break;
	default:
		LOG_INF("Unknown event received");
		break;
	}
}

void AppTask::ActionInitiated(LightingManager::Action aAction)
{
	if (aAction == LightingManager::Action::On) {
		LOG_INF("Turn On Action has been initiated");
	} else if (aAction == LightingManager::Action::Off) {
		LOG_INF("Turn Off Action has been initiated");
	} else if (aAction == LightingManager::Action::Level) {
		LOG_INF("Level Action has been initiated");
	}
}

void AppTask::ActionCompleted(LightingManager::Action aAction)
{
	if (aAction == LightingManager::Action::On) {
		LOG_INF("Turn On Action has been completed");
	} else if (aAction == LightingManager::Action::Off) {
		LOG_INF("Turn Off Action has been completed");
	} else if (aAction == LightingManager::Action::Level) {
		LOG_INF("Level Action has been completed");
	}

	if (!LightingMgr().IsActionChipInitiated()) {
		sAppTask.UpdateClusterState();
	}
}

void AppTask::FunctionPressHandler()
{
	if (!sAppTask.mFunctionTimerActive) {
		sAppTask.StartFunctionTimer(kFactoryResetTriggerTimeout);
		sAppTask.mFunction = kFunction_SoftwareUpdate;
	}
}

void AppTask::FunctionReleaseHandler()
{
	if (sAppTask.mFunctionTimerActive && sAppTask.mFunction == kFunction_SoftwareUpdate) {
		sAppTask.CancelFunctionTimer();
		sAppTask.mFunction = kFunction_NoneSelected;

#if defined(CONFIG_MCUMGR_SMP_BT) && defined(CONFIG_MCUMGR_CMD_IMG_MGMT) && defined(CONFIG_MCUMGR_CMD_OS_MGMT)
		if (!sAppTask.mSoftwareUpdateEnabled) {
			sAppTask.mSoftwareUpdateEnabled = true;
			os_mgmt_register_group();
			img_mgmt_register_group();
			img_mgmt_set_upload_cb(SoftwareUpdateConfirmationHandler, NULL);
			smp_bt_register();

			LOG_INF("Enabled software update");
		} else {
			LOG_INF("Software update is already enabled");
		}

#else
		LOG_INF("Software update is disabled");
#endif

	} else if (sAppTask.mFunctionTimerActive && sAppTask.mFunction == kFunction_FactoryReset) {
		sUnusedLED_1.Set(false);
		sUnusedLED.Set(false);

		sAppTask.CancelFunctionTimer();
		sAppTask.mFunction = kFunction_NoneSelected;
		LOG_INF("Factory Reset has been Canceled");
	}
}

void AppTask::FunctionTimerEventHandler()
{
	if (sAppTask.mFunctionTimerActive && sAppTask.mFunction == kFunction_SoftwareUpdate) {
		LOG_INF("Factory Reset Triggered. Release button within %ums to cancel.", kFactoryResetCancelWindow);
		sAppTask.StartFunctionTimer(kFactoryResetCancelWindow);
		sAppTask.mFunction = kFunction_FactoryReset;

		/* Turn off all LEDs before starting blink to make sure blink is co-ordinated. */
		sStatusLED.Set(false);
		sUnusedLED_1.Set(false);
		sUnusedLED.Set(false);

		sStatusLED.Blink(500);
		sUnusedLED.Blink(500);
		sUnusedLED_1.Blink(500);

	} else if (sAppTask.mFunctionTimerActive && sAppTask.mFunction == kFunction_FactoryReset) {
		sAppTask.mFunction = kFunction_NoneSelected;
		LOG_INF("Factory Reset triggered");
		ConfigurationMgr().InitiateFactoryReset();
	}
}

void AppTask::StartThreadHandler()
{
	if (AddTestPairing() != CHIP_NO_ERROR) {
		LOG_ERR("Failed to add test pairing");
	}

	if (!ConnectivityMgr().IsThreadProvisioned()) {
		StartDefaultThreadNetwork();
		LOG_INF("Device is not commissioned to a Thread network. Starting with the default configuration");
	} else {
		LOG_INF("Device is commissioned to a Thread network");
	}

	sLightBulbPublishService.Start(10000, 1000);
}

void AppTask::StartBLEAdvertisingHandler()
{
	if (chip::DeviceLayer::ConnectivityMgr().IsThreadProvisioned() && !sAppTask.mSoftwareUpdateEnabled) {
		LOG_INF("NFC Tag emulation and BLE advertisement not started - device is commissioned to a Thread network.");
		return;
	}

#ifdef CONFIG_CHIP_NFC_COMMISSIONING
	if (NFCMgr().IsTagEmulationStarted()) {
		LOG_INF("NFC Tag emulation is already started");
	} else {
		ShareQRCodeOverNFC(chip::RendezvousInformationFlags(chip::RendezvousInformationFlag::kBLE));
	}
#endif

	if (ConnectivityMgr().IsBLEAdvertisingEnabled()) {
		LOG_INF("BLE Advertisement is already enabled");
		return;
	}

	if (OpenDefaultPairingWindow(chip::ResetAdmins::kNo) == CHIP_NO_ERROR) {
		LOG_INF("Enabled BLE Advertisement");
	} else {
		LOG_ERR("OpenDefaultPairingWindow() failed");
	}
}

#ifdef CONFIG_CHIP_NFC_COMMISSIONING
void AppTask::ThreadProvisioningHandler(const ChipDeviceEvent *event, intptr_t)
{
	if (event->Type == DeviceEventType::kCHIPoBLEAdvertisingChange &&
	    event->CHIPoBLEAdvertisingChange.Result == kActivity_Stopped) {
		NFCMgr().StopTagEmulation();
	}
}
#endif

void AppTask::ButtonEventHandler(uint32_t buttonState, uint32_t hasChanged)
{
	if (DK_BTN1_MSK & buttonState & hasChanged) {
		GetAppTask().PostEvent(AppEvent{ AppEvent::FunctionPress });
	} else if (DK_BTN1_MSK & hasChanged) {
		GetAppTask().PostEvent(AppEvent{ AppEvent::FunctionRelease });
	}

	if (DK_BTN2_MSK & buttonState & hasChanged) {
		GetAppTask().PostEvent(AppEvent{ AppEvent::Toggle, 0, false });
	}

	if (DK_BTN3_MSK & buttonState & hasChanged) {
		GetAppTask().PostEvent(AppEvent{ AppEvent::StartThread });
	}

	if (DK_BTN4_MSK & buttonState & hasChanged) {
		GetAppTask().PostEvent(AppEvent{ AppEvent::StartBleAdvertising });
	}
}

void AppTask::CancelFunctionTimer()
{
	k_timer_stop(&sFunctionTimer);
	mFunctionTimerActive = false;
}

void AppTask::StartFunctionTimer(uint32_t timeoutInMs)
{
	k_timer_start(&sFunctionTimer, K_MSEC(timeoutInMs), K_NO_WAIT);
	mFunctionTimerActive = true;
}

void AppTask::TimerEventHandler(k_timer *timer)
{
	GetAppTask().PostEvent(AppEvent{ AppEvent::FunctionTimer });
}
```

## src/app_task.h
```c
/*
 * Copyright (c) 2021 Nordic Semiconductor ASA
 *
 * SPDX-License-Identifier: LicenseRef-Nordic-5-Clause
 */

#pragma once

#include "app_event.h"
#include "lighting_manager.h"

#include <platform/CHIPDeviceLayer.h>

struct k_timer;

class AppTask {
public:
	static constexpr size_t APP_EVENT_QUEUE_SIZE = 10;

	int StartApp();

	void PostEvent(const AppEvent &aEvent);
	void UpdateClusterState();

private:
	int Init();

	void CancelFunctionTimer();
	void StartFunctionTimer(uint32_t timeoutInMs);

	void DispatchEvent(const AppEvent &event);
	void FunctionPressHandler();
	void FunctionReleaseHandler();
	void FunctionTimerEventHandler();
	void StartThreadHandler();
	void StartBLEAdvertisingHandler();

#ifdef CONFIG_CHIP_NFC_COMMISSIONING
	int StartNFCTag();
#endif

	static void ActionInitiated(LightingManager::Action aAction);
	static void ActionCompleted(LightingManager::Action aAction);
	static void ButtonEventHandler(uint32_t buttonState, uint32_t hasChanged);
	static void TimerEventHandler(k_timer *timer);
	static void ThreadProvisioningHandler(const chip::DeviceLayer::ChipDeviceEvent *event, intptr_t arg);
	static int SoftwareUpdateConfirmationHandler(uint32_t offset, uint32_t size, void *arg);

	friend AppTask &GetAppTask();

	enum Function_t {
		kFunction_NoneSelected = 0,
		kFunction_SoftwareUpdate = 0,
		kFunction_FactoryReset,

		kFunction_Invalid
	};

	Function_t mFunction = kFunction_NoneSelected;

	static AppTask sAppTask;
	bool mFunctionTimerActive = false;
	bool mSoftwareUpdateEnabled = false;
};

inline AppTask &GetAppTask()
{
	return AppTask::sAppTask;
}
```

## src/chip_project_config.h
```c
/*
 * Copyright (c) 2021 Nordic Semiconductor ASA
 *
 * SPDX-License-Identifier: LicenseRef-BSD-5-Clause-Nordic
 */

/**
 *    @file
 *          Example project configuration file for CHIP.
 *
 *          This is a place to put application or project-specific overrides
 *          to the default configuration values for general CHIP features.
 *
 */

#pragma once

/* Use a default pairing code if one hasn't been provisioned in flash. */
#define CHIP_DEVICE_CONFIG_USE_TEST_SETUP_PIN_CODE 12345678
#define CHIP_DEVICE_CONFIG_USE_TEST_SETUP_DISCRIMINATOR 0xF00

#define LIGHT_BULB_PWM_DEVICE	DT_PWMS_LABEL(DT_ALIAS(pwm_led1))
#define LIGHT_BULB_PWM_CHANNEL	DT_PWMS_CHANNEL(DT_ALIAS(pwm_led1))
```
